# SEQ register map
Vendor: Texas Instruments
Peripheral module from a debugger description file (folder omap36xx).
Registers are 32-bit, access not given, reset 0x0 unless marked. A register's access mark holds for its fields unless they carry their own. Offsets are as the file gives them; lines under a group give offsets from that group; [hi:lo] are bit positions; {n}, {i} and the like mark numbered series; 'fields as' and 'values as' point back to an identical list; <NAME> marks a mode.

## SEQ
0x00 SEQ_REVISION ro (reset mask 0xFFFFFF00) — This register contains the IP revision code (reset value to be defined by design team for each version of the module)
  [7:0] REV — IP revision3:0 Minor revision7:4 Major revision
0x08 SEQ_SYSCONFIG rw reset 0x1 — This register allows controlling various parameters of the sequencer module
  [0] AUTOIDLE — Internal auto-clock gating strategy0: Clock is free running1: Automatic clock gating strategy is applied
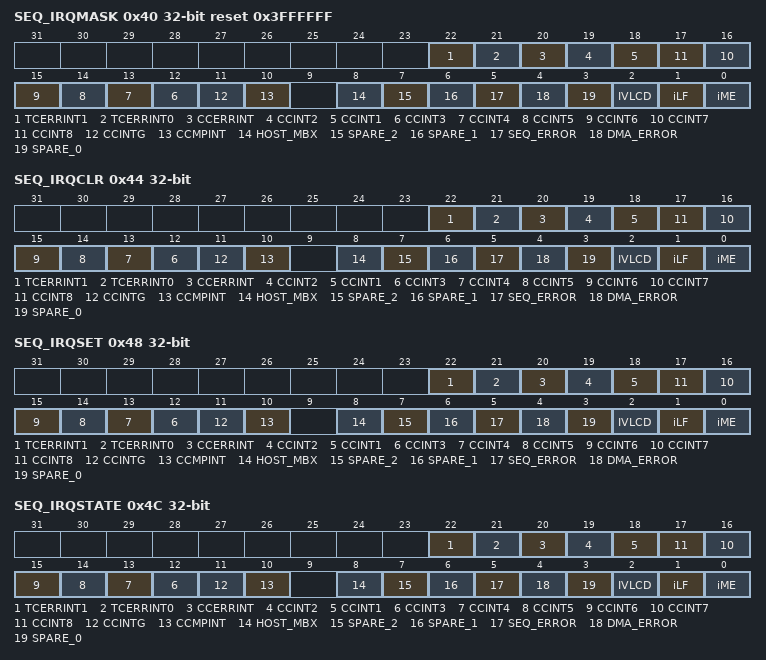
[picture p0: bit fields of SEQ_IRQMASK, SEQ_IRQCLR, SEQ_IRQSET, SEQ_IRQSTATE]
0x40 SEQ_IRQMASK reset 0x3FFFFFF — This register contains the interrupt mask bits: when.MirqN is set, input event N does not trigger the interrupt line to the sequencer (default) when .MirqN is clear, input event N triggers the interrupt line to the sequencer
  [22] TCERRINT1 — TCERRINT1 IRQ mask (access w/1toSet)
  [21] TCERRINT0 — TCERRINT0 IRQ mask (access w/1toSet)
  [20] CCERRINT — CCERRINT IRQ mask (access w/1toSet)
  [19] CCINT2 — CCINT2 IRQ mask (access w/1toSet)
  [18] CCINT1 — CCINT1 IRQ mask (access w/1toSet)
  [n+9] CCINT{n} (n=3..8) — CCINT{n} IRQ mask (access w/1toSet)
  [11] CCINTG — CCINTG IRQ mask (access w/1toSet)
  [10] CCMPINT — CCMPINT IRQ mask (access w/1toSet)
  [8] HOST_MBX — HOST_MBX IRQ mask (access w/1toSet)
  [7] SPARE_2 — Spare #2 interrupt mask (reserved for future use)Reads returns 0Write 0 for SW forward compatibility (access w/1toSet)
  [6] SPARE_1 — Spare #1 interrupt mask (reserved for future use)Reads returns 0Write 0 for SW forward compatibility (access w/1toSet)
  [5] SEQ_ERROR — SEQ_ERROR IRQ mask (access w/1toSet)
  [4] DMA_ERROR — DMA_ERROR IRQ mask (access w/1toSet)
  [3] SPARE_0 — Spare #0 interrupt mask (reserved for future use)Reads returns 0Write 0 for SW forward compatibility (access w/1toSet)
  [2] IVLCD — iVLCD IRQ mask (access w/1toSet)
  [1] iLF — iLF IRQ mask (access w/1toSet)
  [0] iME — iME IRQ mask (access w/1toSet)
0x44 SEQ_IRQCLR
  [22] TCERRINT1 — TCERRINT1 IRQ clear (access w/1toSet)
  [21] TCERRINT0 — TCERRINT0 IRQ clear (access w/1toSet)
  [20] CCERRINT — CCERRINT IRQ clear (access w/1toSet)
  [19] CCINT2 — CCINT2 IRQ clear (access w/1toSet)
  [18] CCINT1 — CCINT1 IRQ clear (access w/1toSet)
  [n+9] CCINT{n} (n=3..8) — CCINT{n} IRQ clear (access w/1toSet)
  [11] CCINTG — CCINTG IRQ clear (access w/1toSet)
  [10] CCMPINT — CCMPINT IRQ clear (access w/1toSet)
  [8] HOST_MBX — HOST_MBX IRQ clear (access w/1toSet)
  [7] SPARE_2 — Spare #2 interrupt clear (reserved for future use)Reads returns 0Write 0 for SW forward compatibility (access w/1toSet)
  [6] SPARE_1 — Spare #1 interrupt clear (reserved for future use)Reads returns 0Write 0 for SW forward compatibility (access w/1toSet)
  [5] SEQ_ERROR — SEQ_ERROR IRQ clear (access w/1toSet)
  [4] DMA_ERROR — DMA_ERROR IRQ clear (access w/1toSet)
  [3] SPARE_0 — Spare #0 interrupt clear (reserved for future use)Reads returns 0Write 0 for SW forward compatibility (access w/1toSet)
  [2] IVLCD — iVLCD IRQ clear (access w/1toSet)
  [1] iLF — iLF IRQ clear (access w/1toSet)
  [0] iME — iME IRQ clear (access w/1toSet)
0x48 SEQ_IRQSET — This register is used to set the interrupt bits (used to test interrupt): write 0: no effect write 1: sets the corresponding bit in the register, and triggers the interrupt line if not already active and the associated event is enabled in reads always return 0
  [22] TCERRINT1 — TCERRINT1 IRQ set (access w/1toSet)
  [21] TCERRINT0 — TCERRINT0 IRQ set (access w/1toSet)
  [20] CCERRINT — CCERRINT IRQ set (access w/1toSet)
  [19] CCINT2 — CCINT2 IRQ set (access w/1toSet)
  [18] CCINT1 — CCINT1 IRQ set (access w/1toSet)
  [n+9] CCINT{n} (n=3..8) — CCINT{n} IRQ set (access w/1toSet)
  [11] CCINTG — CCINTG IRQ set (access w/1toSet)
  [10] CCMPINT — CCMPINT IRQ set (access w/1toSet)
  [8] HOST_MBX — HOST_MBX IRQ set (access w/1toSet)
  [7] SPARE_2 — Spare #2 interrupt set (reserved for future use)Reads returns 0Write 0 for SW forward compatibility (access w/1toSet)
  [6] SPARE_1 — Spare #1 interrupt set (reserved for future use)Reads returns 0Write 0 for SW forward compatibility (access w/1toSet)
  [5] SEQ_ERROR — SEQ_ERROR IRQ set (access w/1toSet)
  [4] DMA_ERROR — DMA_ERROR IRQ set (access w/1toSet)
  [3] SPARE_0 — Spare #0 interrupt set (reserved for future use)Reads returns 0Write 0 for SW forward compatibility (access w/1toSet)
  [2] IVLCD — iVLCD IRQ set (access w/1toSet)
  [1] iLF — iLF IRQ set (access w/1toSet)
  [0] iME — iME IRQ set (access w/1toSet)
0x4C SEQ_IRQSTATE ro — This register holds the interrupt status bits
  [22] TCERRINT1 — TCERRINT1 IRQ status
  [21] TCERRINT0 — TCERRINT0 IRQ status
  [20] CCERRINT — CCERRINT IRQ status
  [19] CCINT2 — CCINT2 IRQ status
  [18] CCINT1 — CCINT1 IRQ status
  [n+9] CCINT{n} (n=3..8) — CCINT{n} IRQ status
  [11] CCINTG — CCINTG IRQ status
  [10] CCMPINT — CCMPINT IRQ status
  [8] HOST_MBX — HOST_MBX IRQ status
  [7] SPARE_2 — Spare #2 interrupt set (reserved for future use)Reads returns 0
  [6] SPARE_1 — Spare #1 interrupt set (reserved for future use)Reads returns 0
  [5] SEQ_ERROR — SEQ_ERROR IRQ status
  [4] DMA_ERROR — DMA_ERROR IRQ status
  [3] SPARE_0 — Spare #0 interrupt set (reserved for future use)Reads returns 0
  [2] IVLCD — iVLCD IRQ status
  [1] iLF — iLF IRQ status
  [0] iME — iME IRQ status
0x60 SEQ_SWICLR — This register is used to clear the software interrupt bit
  [0] SWICLR — SW interrupt clear (access w/1toSet)
0x64 SEQ_SWISET — This register is used to set the software interrupt bit
  [0] SWISET — SW interrupt set (access w/1toSet)
0x68 SEQ_SWISTATE — This register holds the SW interrupt status
  [0] SWISTATE — SW interrupt status (access w/1toSet)
